# Port_Mapping_Port_4_1 register map
Vendor: Texas Instruments
Peripheral module from a debugger description file (folder msp430).
Registers are 8-bit, read-write, reset 0x0 unless marked. A register's access mark holds for its fields unless they carry their own. Offsets are as the file gives them; lines under a group give offsets from that group; [hi:lo] are bit positions; {n}, {i} and the like mark numbered series; 'fields as' and 'values as' point back to an identical list; <NAME> marks a mode.

## Port_Mapping_Port_4
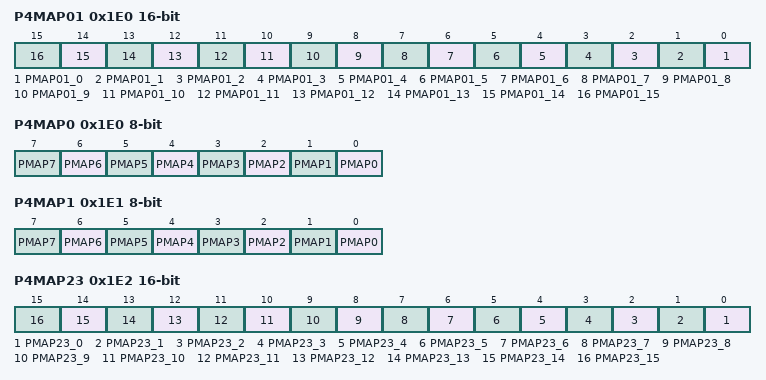
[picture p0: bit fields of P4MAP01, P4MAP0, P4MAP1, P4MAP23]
0x1E0 P4MAP01 16-bit — Port P4.0/1 mapping register
  [n] PMAP01_{n} (n=0..15)
0x1E0 P4MAP0 — Port P4.0 mapping register
  [n] PMAP{n} (n=0..7)
0x1E1 P4MAP1 — Port P4.1 mapping register
  [n] PMAP{n} (n=0..7)
0x1E2 P4MAP23 16-bit — Port P4.2/3 mapping register
  [n] PMAP23_{n} (n=0..15)
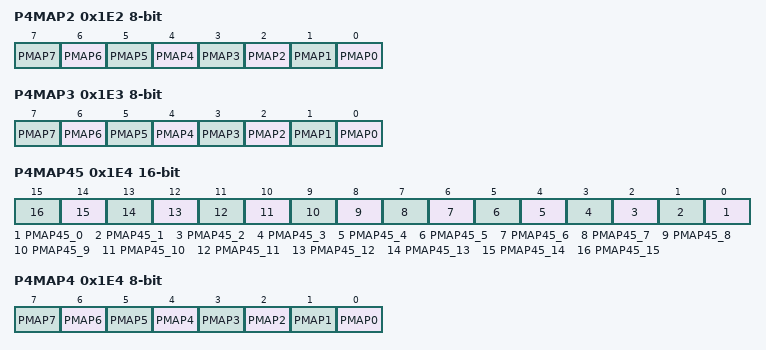
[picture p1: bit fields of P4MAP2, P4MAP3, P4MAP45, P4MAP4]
0x1E2 P4MAP2 — Port P4.2 mapping register
  [n] PMAP{n} (n=0..7)
0x1E3 P4MAP3 — Port P4.3 mapping register
  [n] PMAP{n} (n=0..7)
0x1E4 P4MAP45 16-bit — Port P4.4/5 mapping register
  [n] PMAP45_{n} (n=0..15)
0x1E4 P4MAP4 — Port P4.4 mapping register
  [n] PMAP{n} (n=0..7)
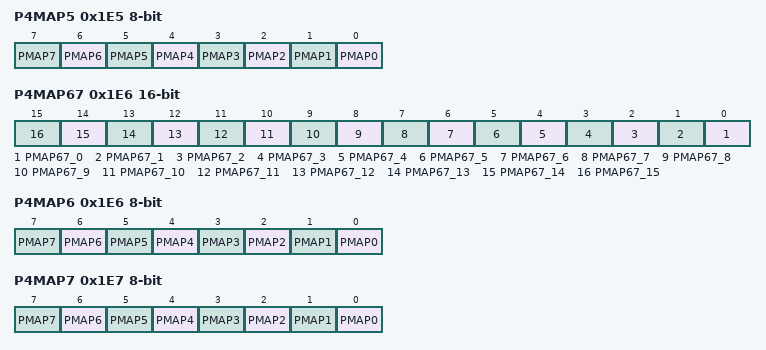
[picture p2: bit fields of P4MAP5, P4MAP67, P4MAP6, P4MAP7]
0x1E5 P4MAP5 — Port P4.5 mapping register
  [n] PMAP{n} (n=0..7)
0x1E6 P4MAP67 16-bit — Port P4.6/7 mapping register
  [n] PMAP67_{n} (n=0..15)
0x1E6 P4MAP6 — Port P4.6 mapping register
  [n] PMAP{n} (n=0..7)
0x1E7 P4MAP7 — Port P4.7 mapping register
  [n] PMAP{n} (n=0..7)
